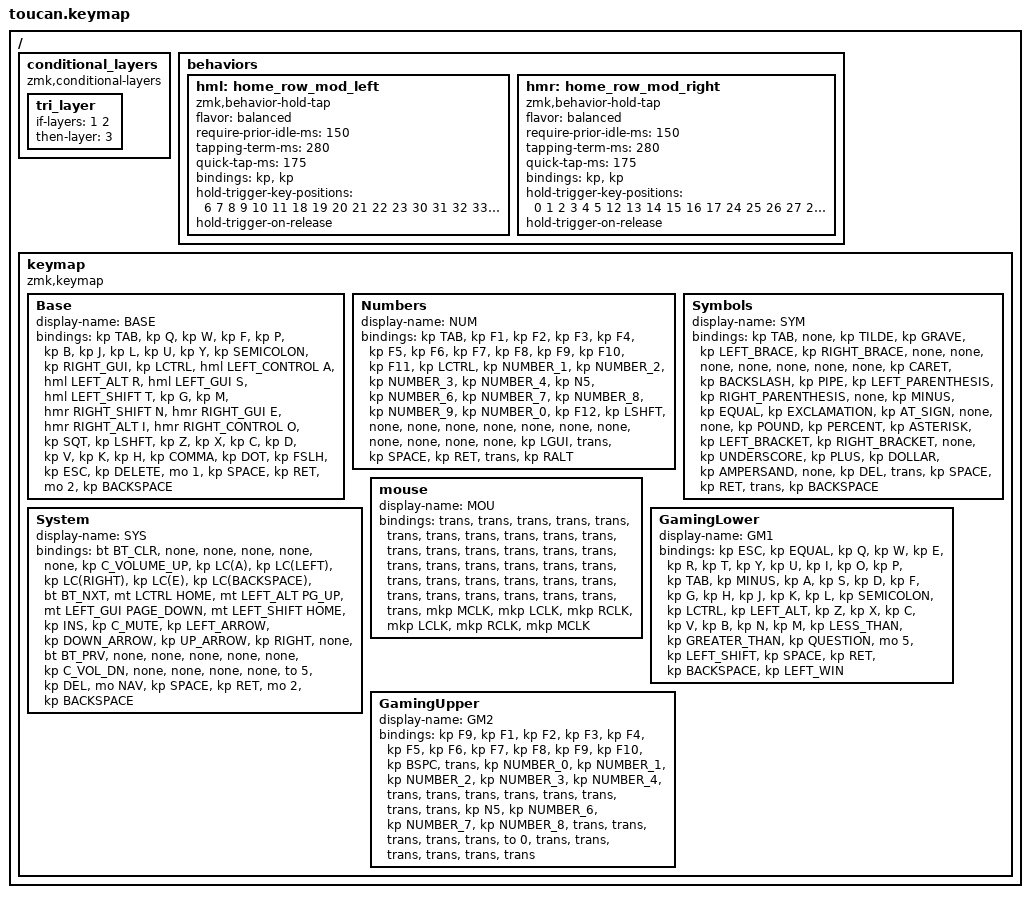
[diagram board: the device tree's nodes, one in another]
#include <behaviors.dtsi>
#include <dt-bindings/zmk/bt.h>
#include <dt-bindings/zmk/keys.h>
#include <dt-bindings/zmk/pointing.h>

#define BASE 0
#define NAV  1
#define SYM  2
#define ADJ  3

/ {
    conditional_layers {
        compatible = "zmk,conditional-layers";

        tri_layer {
            if-layers = <1 2>;
            then-layer = <3>;
        };
    };

    behaviors {
        hml: home_row_mod_left {
            compatible = "zmk,behavior-hold-tap";
            #binding-cells = <2>;
            flavor = "balanced";
            require-prior-idle-ms = <150>;
            tapping-term-ms = <280>;
            quick-tap-ms = <175>;
            bindings = <&kp>, <&kp>;
            hold-trigger-key-positions = < 6 7 8 9 10 11 18 19 20 21 22 23 30 31 32 33 34 35 >; // List of keys on the right side of the keyboard
            hold-trigger-on-release;
        };
        hmr: home_row_mod_right {
            compatible = "zmk,behavior-hold-tap";
            #binding-cells = <2>;
            flavor = "balanced";
            require-prior-idle-ms = <150>;
            tapping-term-ms = <280>;
            quick-tap-ms = <175>;
            bindings = <&kp>, <&kp>;
            hold-trigger-key-positions = < 0 1 2 3 4 5 12 13 14 15 16 17 24 25 26 27 28 29 >; // List of keys on the left side of the keyboard
            hold-trigger-on-release;
        };
    };

    keymap {
        compatible = "zmk,keymap";

        Base {
            display-name = "BASE";
            bindings = <
&kp TAB  &kp Q  &kp W  &kp F  &kp P  &kp B  &kp J  &kp L  &kp U  &kp Y  &kp SEMICOLON  &kp RIGHT_GUI  &kp LCTRL  &hml LEFT_CONTROL A  &hml LEFT_ALT R  &hml LEFT_GUI S  &hml LEFT_SHIFT T  &kp G  &kp M  &hmr RIGHT_SHIFT N  &hmr RIGHT_GUI E  &hmr RIGHT_ALT I  &hmr RIGHT_CONTROL O  &kp SQT  &kp LSHFT  &kp Z  &kp X  &kp C  &kp D  &kp V  &kp K  &kp H  &kp COMMA  &kp DOT  &kp FSLH  &kp ESC  &kp DELETE  &mo 1  &kp SPACE  &kp RET  &mo 2  &kp BACKSPACE
            >;
        };

        Numbers {
            display-name = "NUM";
            bindings = <
&kp TAB  &kp F1  &kp F2  &kp F3  &kp F4  &kp F5  &kp F6  &kp F7  &kp F8  &kp F9  &kp F10  &kp F11  &kp LCTRL  &kp NUMBER_1  &kp NUMBER_2  &kp NUMBER_3  &kp NUMBER_4  &kp N5  &kp NUMBER_6  &kp NUMBER_7  &kp NUMBER_8  &kp NUMBER_9  &kp NUMBER_0  &kp F12  &kp LSHFT  &none  &none  &none  &none  &none  &none  &none  &none  &none  &none  &none  &kp LGUI  &trans  &kp SPACE  &kp RET  &trans  &kp RALT
            >;
        };

        Symbols {
            display-name = "SYM";
            bindings = <
&kp TAB  &none  &kp TILDE  &kp GRAVE  &kp LEFT_BRACE  &kp RIGHT_BRACE  &none  &none  &none  &none  &none  &none  &none  &kp CARET  &kp BACKSLASH  &kp PIPE  &kp LEFT_PARENTHESIS  &kp RIGHT_PARENTHESIS  &none  &kp MINUS  &kp EQUAL  &kp EXCLAMATION  &kp AT_SIGN  &none  &none  &kp POUND  &kp PERCENT  &kp ASTERISK  &kp LEFT_BRACKET  &kp RIGHT_BRACKET  &none  &kp UNDERSCORE  &kp PLUS  &kp DOLLAR  &kp AMPERSAND  &none  &kp DEL  &trans  &kp SPACE  &kp RET  &trans  &kp BACKSPACE
            >;
        };

        System {
            display-name = "SYS";
            bindings = <
&bt BT_CLR  &none  &none  &none  &none  &none  &kp C_VOLUME_UP  &kp LC(A)  &kp LC(LEFT)  &kp LC(RIGHT)  &kp LC(E)  &kp LC(BACKSPACE)  &bt BT_NXT  &mt LCTRL HOME  &mt LEFT_ALT PG_UP  &mt LEFT_GUI PAGE_DOWN  &mt LEFT_SHIFT HOME  &kp INS  &kp C_MUTE  &kp LEFT_ARROW  &kp DOWN_ARROW  &kp UP_ARROW  &kp RIGHT  &none  &bt BT_PRV  &none  &none  &none  &none  &none  &kp C_VOL_DN  &none  &none  &none  &none  &to 5  &kp DEL  &mo NAV  &kp SPACE  &kp RET  &mo 2  &kp BACKSPACE
            >;
        };

        mouse {
            display-name = "MOU";
            bindings = <
&trans  &trans  &trans  &trans  &trans  &trans  &trans  &trans  &trans  &trans  &trans  &trans  &trans  &trans  &trans  &trans  &trans  &trans  &trans  &trans  &trans  &trans  &trans  &trans  &trans  &trans  &trans  &trans  &trans  &trans  &trans  &trans  &trans  &trans  &trans  &trans  &mkp MCLK  &mkp LCLK  &mkp RCLK  &mkp LCLK  &mkp RCLK  &mkp MCLK
            >;
        };

        GamingLower {
            display-name = "GM1";
            bindings = <
&kp ESC  &kp EQUAL  &kp Q  &kp W  &kp E  &kp R  &kp T  &kp Y  &kp U  &kp I  &kp O  &kp P  &kp TAB  &kp MINUS  &kp A  &kp S  &kp D  &kp F  &kp G  &kp H  &kp J  &kp K  &kp L  &kp SEMICOLON  &kp LCTRL  &kp LEFT_ALT  &kp Z  &kp X  &kp C  &kp V  &kp B  &kp N  &kp M  &kp LESS_THAN  &kp GREATER_THAN  &kp QUESTION  &mo 5  &kp LEFT_SHIFT  &kp SPACE  &kp RET  &kp BACKSPACE  &kp LEFT_WIN
            >;
        };

        GamingUpper {
            display-name = "GM2";
            bindings = <
&kp F9  &kp F1  &kp F2  &kp F3  &kp F4  &kp F5  &kp F6  &kp F7  &kp F8  &kp F9  &kp F10  &kp BSPC  &trans  &kp NUMBER_0  &kp NUMBER_1  &kp NUMBER_2  &kp NUMBER_3  &kp NUMBER_4  &trans  &trans  &trans  &trans  &trans  &trans  &trans  &trans  &kp N5  &kp NUMBER_6  &kp NUMBER_7  &kp NUMBER_8  &trans  &trans  &trans  &trans  &trans  &to 0  &trans  &trans  &trans  &trans  &trans  &trans
            >;
        };
    };
};
